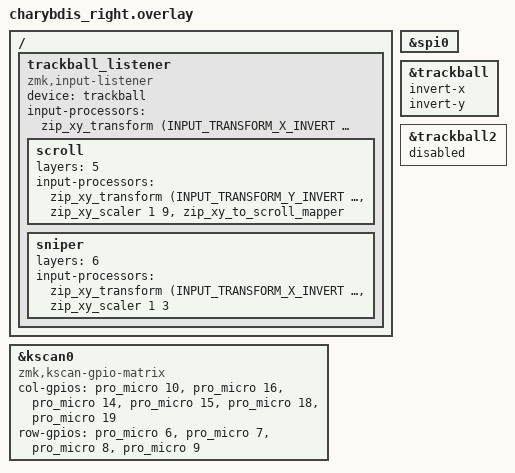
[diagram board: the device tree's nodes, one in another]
#include "charybdis.dtsi"
#include "charybdis_3610.dtsi"
#include <dt-bindings/zmk/input_transform.h>
#include <input/processors.dtsi>

&kscan0 {
	compatible = "zmk,kscan-gpio-matrix";

	col-gpios
		= <&pro_micro 10 GPIO_ACTIVE_HIGH>
		, <&pro_micro 16 GPIO_ACTIVE_HIGH>
		, <&pro_micro 14 GPIO_ACTIVE_HIGH>
		, <&pro_micro 15 GPIO_ACTIVE_HIGH>
		, <&pro_micro 18 GPIO_ACTIVE_HIGH>
		, <&pro_micro 19 GPIO_ACTIVE_HIGH>
		;
	row-gpios
		= <&pro_micro 6 (GPIO_ACTIVE_HIGH | GPIO_PULL_DOWN)>
		, <&pro_micro 7 (GPIO_ACTIVE_HIGH | GPIO_PULL_DOWN)>
		, <&pro_micro 8 (GPIO_ACTIVE_HIGH | GPIO_PULL_DOWN)>
		, <&pro_micro 9 (GPIO_ACTIVE_HIGH | GPIO_PULL_DOWN)>
		;
};

&spi0 {
	status = "okay";
};

&trackball {
	invert-x;
	invert-y;
};

&trackball2 {
	status = "disabled";
};

/ {
	trackball_listener {
		compatible = "zmk,input-listener";
		device = <&trackball>;
		input-processors = <&zip_xy_transform (INPUT_TRANSFORM_X_INVERT | INPUT_TRANSFORM_Y_INVERT | INPUT_TRANSFORM_XY_SWAP)>;

		scroll {
			layers = <5>;
			input-processors = <&zip_xy_transform (INPUT_TRANSFORM_Y_INVERT | INPUT_TRANSFORM_XY_SWAP)>, <&zip_xy_scaler 1 9>, <&zip_xy_to_scroll_mapper>;
		};

		sniper {
			layers = <6>;
			input-processors = <&zip_xy_transform (INPUT_TRANSFORM_X_INVERT | INPUT_TRANSFORM_Y_INVERT | INPUT_TRANSFORM_XY_SWAP)>, <&zip_xy_scaler 1 3>;
		};
	};
};
